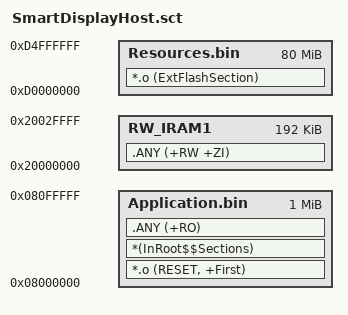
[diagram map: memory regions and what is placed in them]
; *************************************************************
; *** Scatter-Loading Description File generated by uVision ***
; *************************************************************

LR_IROM1 0x08000000 0x00100000  {    ; load region size_region
  Application.bin 0x08000000 0x00100000  {  ; load address = execution address
   *.o (RESET, +First)
   *(InRoot$$Sections)
   .ANY (+RO)
  }
  RW_IRAM1 0x20000000 0x00030000  {  ; RW data
   .ANY (+RW +ZI)
  }
  
}


LR_EROM3 0xD0000000 0x5000000 { ; load region size_region
  Resources.bin 0xD0000000 0x5000000 { ; load address = execution address
    *.o (ExtFlashSection)
  }
}
